AUTOSAR XML (schema 00049)
package /Application/DltConfig
  dlt log channel to process mapping DltLogChannelToProcessMapping_ServiceCreator_TO_ServiceCreator: dlt-log-channel=ServiceCreator, process=ServiceCreator
package /Application/Executable
  executable ServiceCreator: category=APPLICATION_LEVEL, logging-behavior=USES-LOGGING, reporting-behavior=REPORTS-EXECUTION-STATE, version=1.0.0
    root sw component prototype AA: application-type=ServiceCreator
package /Application/Manifest
  18 x service instance to port prototype mapping:
    ServiceCreator_AA_PPort_BCM_ExteriorSignal: port-prototype=AA.PPort_BCM_ExteriorSignal, service-instance=EEVP_ServiceCreator_Provider_BCM_ExteriorSignal
    ServiceCreator_AA_PPort_BCM_WiperWash: port-prototype=AA.PPort_BCM_WiperWash, service-instance=EEVP_ServiceCreator_Provider_BCM_WiperWash
    ServiceCreator_AA_PPort_Ctrl_MoodLamp: port-prototype=AA.PPort_Ctrl_MoodLamp, service-instance=EEVP_ServiceCreator_Provider_Ctrl_MoodLamp
    ServiceCreator_AA_PPort_Ctrl_RearCurtain: port-prototype=AA.PPort_Ctrl_RearCurtain, service-instance=EEVP_ServiceCreator_Provider_Ctrl_RearCurtain
    ServiceCreator_AA_PPort_Snsr_FaceDetectModule: port-prototype=AA.PPort_Snsr_FaceDetectModule, service-instance=EEVP_ServiceCreator_Provider_Snsr_FaceDetectModule
    ServiceCreator_AA_PPort_Snsr_HeartBeat: port-prototype=AA.PPort_Snsr_HeartBeat, service-instance=EEVP_ServiceCreator_Provider_Snsr_Heartbeat
    ServiceCreator_AA_PPort_Snsr_USS: port-prototype=AA.PPort_Snsr_USS, service-instance=EEVP_ServiceCreator_Provider_Snsr_USS
    ServiceCreator_AA_PPort_TMS_AC: port-prototype=AA.PPort_TMS_AC, service-instance=EEVP_ServiceCreator_Provider_TMS_AC
    ServiceCreator_AA_PPort_TMS_EnvMonitor: port-prototype=AA.PPort_TMS_EnvMonitor, service-instance=EEVP_ServiceCreator_Provider_TMS_EnvMonitor
    ServiceCreator_AA_PPort_TMS_Fragrance: port-prototype=AA.PPort_TMS_Fragrance, service-instance=EEVP_ServiceCreator_Provider_TMS_Fragrance
    ServiceCreator_AA_PPort_TMS_Purifier: port-prototype=AA.PPort_TMS_Purifier, service-instance=EEVP_ServiceCreator_Provider_TMS_Purifier
    ServiceCreator_AA_PPort_TMS_Ventilation: port-prototype=AA.PPort_TMS_Ventilation, service-instance=EEVP_ServiceCreator_Provider_TMS_Ventilation
    ServiceCreator_AA_PPort_VCS_AccrPedal: port-prototype=AA.PPort_VCS_AccrPedal, service-instance=EEVP_ServiceCreator_Provider_VCS_AccrPedal
    ServiceCreator_AA_PPort_VCS_Brake: port-prototype=AA.PPort_VCS_Brake, service-instance=EEVP_ServiceCreator_Provider_VCS_Brake
    ServiceCreator_AA_PPort_VCS_BrakePedal: port-prototype=AA.PPort_VCS_BrakePedal, service-instance=EEVP_ServiceCreator_Provider_VCS_BrakePedal
    ServiceCreator_AA_PPort_VCS_EPB: port-prototype=AA.PPort_VCS_EPB, service-instance=EEVP_ServiceCreator_Provider_VCS_EPB
    ServiceCreator_AA_PPort_VCS_Gear: port-prototype=AA.PPort_VCS_Gear, service-instance=EEVP_ServiceCreator_Provider_VCS_Gear
    ServiceCreator_AA_PPort_VCS_VehSpd: port-prototype=AA.PPort_VCS_VehSpd, service-instance=EEVP_ServiceCreator_Provider_VCS_VehSpd
package /Application/Process
  process ServiceCreator: executable=ServiceCreator, state-dependent-startup-config{function-group-state=[SFG03.On, SFG03.Verify], resource-group=DefaultResourceGroup, startup-config=DefaultStartupConfig}
    process state machine ServiceCreator: type=ProcessState
package /Application/SwComponent
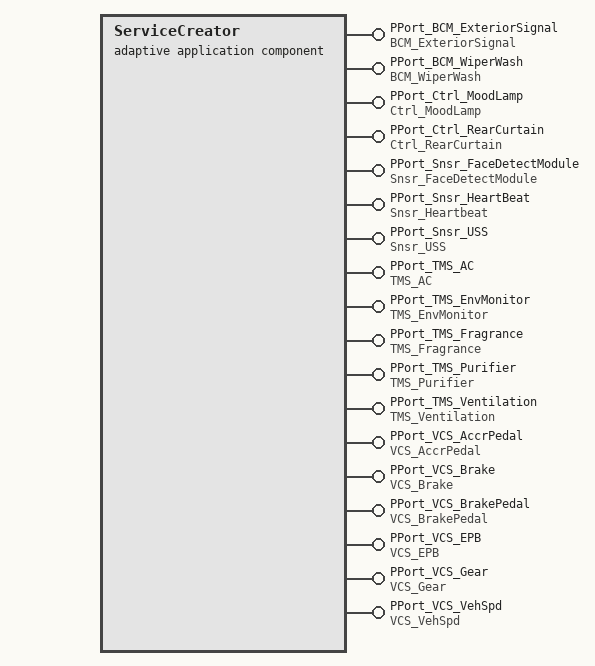
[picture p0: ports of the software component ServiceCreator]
  adaptive application sw component type ServiceCreator
    18 x provide port:
      PPort_BCM_ExteriorSignal: provided-interface=BCM_ExteriorSignal
      PPort_BCM_WiperWash: provided-interface=BCM_WiperWash
      PPort_Ctrl_MoodLamp: provided-interface=Ctrl_MoodLamp
      PPort_Ctrl_RearCurtain: provided-interface=Ctrl_RearCurtain
      PPort_Snsr_FaceDetectModule: provided-interface=Snsr_FaceDetectModule
      PPort_Snsr_HeartBeat: provided-interface=Snsr_Heartbeat
      PPort_Snsr_USS: provided-interface=Snsr_USS
      PPort_TMS_AC: provided-interface=TMS_AC
      PPort_TMS_EnvMonitor: provided-interface=TMS_EnvMonitor
      PPort_TMS_Fragrance: provided-interface=TMS_Fragrance
      PPort_TMS_Purifier: provided-interface=TMS_Purifier
      PPort_TMS_Ventilation: provided-interface=TMS_Ventilation
      PPort_VCS_AccrPedal: provided-interface=VCS_AccrPedal
      PPort_VCS_Brake: provided-interface=VCS_Brake
      PPort_VCS_BrakePedal: provided-interface=VCS_BrakePedal
      PPort_VCS_EPB: provided-interface=VCS_EPB
      PPort_VCS_Gear: provided-interface=VCS_Gear
      PPort_VCS_VehSpd: provided-interface=VCS_VehSpd
